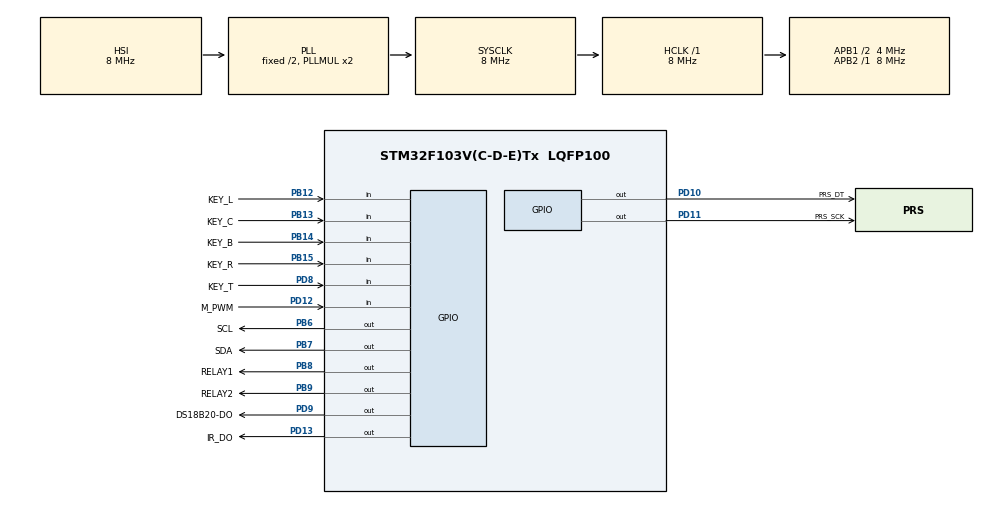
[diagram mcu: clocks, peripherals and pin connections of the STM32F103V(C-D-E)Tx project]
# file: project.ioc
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Mcu.Family=STM32F1
Mcu.Name=STM32F103V(C-D-E)Tx
Mcu.Package=LQFP100
NVIC.PriorityGroup=NVIC_PRIORITYGROUP_4
PA13.Mode=Serial_Wire
PA13.Signal=SYS_JTMS-SWDIO
PA14.Mode=Serial_Wire
PA14.Signal=SYS_JTCK-SWCLK
PB12.GPIO_Label=KEY_L
PB12.Signal=GPIO_Input
PB13.GPIO_Label=KEY_C
PB13.Signal=GPIO_Input
PB14.GPIO_Label=KEY_B
PB14.Signal=GPIO_Input
PB15.GPIO_Label=KEY_R
PB15.Signal=GPIO_Input
PB6.GPIO_Label=SCL
PB6.Signal=GPIO_Output
PB7.GPIO_Label=SDA
PB7.Signal=GPIO_Output
PB8.GPIO_Label=RELAY1
PB8.Signal=GPIO_Output
PB9.GPIO_Label=RELAY2
PB9.Signal=GPIO_Output
PD10.GPIO_Label=PRS_DT
PD10.Signal=GPIO_Output
PD11.GPIO_Label=PRS_SCK
PD11.Signal=GPIO_Output
PD12.GPIO_Label=M_PWM
PD12.Signal=GPIO_Input
PD13.GPIO_Label=IR_DO
PD13.Signal=GPIO_Output
PD8.GPIO_Label=KEY_T
PD8.Signal=GPIO_Input
PD9.GPIO_Label=DS18B20-DO
PD9.Signal=GPIO_Output
ProjectManager.HeapSize=0x200
ProjectManager.StackSize=0x400
ProjectManager.TargetToolchain=MDK-ARM V5.32
RCC.ADCPresc=RCC_ADCPCLK2_DIV6
RCC.AHBFreq_Value=8000000
RCC.APB1CLKDivider=RCC_HCLK_DIV2
RCC.APB1Freq_Value=4000000
RCC.APB1TimFreq_Value=8000000
RCC.APB2Freq_Value=8000000
RCC.APB2TimFreq_Value=8000000
RCC.HCLKFreq_Value=8000000
RCC.SYSCLKFreq_VALUE=8000000
RCC.SYSCLKSource=RCC_SYSCLKSOURCE_PLLCLK
RCC.USBFreq_Value=8000000
board=custom

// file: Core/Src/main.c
/* USER CODE BEGIN Header */
/**
  ******************************************************************************
  * @file           : main.c
  * @brief          : Main program body
  ******************************************************************************
  * @attention
  *
  * Copyright (c) 2026 STMicroelectronics.
  * All rights reserved.
  *
  * This software is licensed under terms that can be found in the LICENSE file
  * in the root directory of this software component.
  * If no LICENSE file comes with this software, it is provided AS-IS.
  *
  ******************************************************************************
  */
/* USER CODE END Header */
#include "main.h"
#include "gpio.h"

/* USER CODE BEGIN Includes */
#include "OLED.h"
/* USER CODE END Includes */

void SystemClock_Config(void);

int main(void)
{

  /* MCU Configuration--------------------------------------------------------*/

  /* Reset of all peripherals, Initializes the Flash interface and the Systick. */
  HAL_Init();

  /* Configure the system clock */
  SystemClock_Config();

  /* Initialize all configured peripherals */
  MX_GPIO_Init();
  /* USER CODE BEGIN 2 */
  OLED_Init();
  /* USER CODE END 2 */

  /* Infinite loop */
  /* USER CODE BEGIN WHILE */
  while (1)
  {

    OLED_DrawRectangle(0, 0, 128, 64, OLED_FILLED);
    OLED_Update();
    /* USER CODE END WHILE */

  }
}

void SystemClock_Config(void)
{
  RCC_OscInitTypeDef RCC_OscInitStruct = {0};
  RCC_ClkInitTypeDef RCC_ClkInitStruct = {0};

  /** Initializes the RCC Oscillators according to the specified parameters
  * in the RCC_OscInitTypeDef structure.
  */
  RCC_OscInitStruct.OscillatorType = RCC_OSCILLATORTYPE_HSI;
  RCC_OscInitStruct.HSIState = RCC_HSI_ON;
  RCC_OscInitStruct.HSICalibrationValue = RCC_HSICALIBRATION_DEFAULT;
  RCC_OscInitStruct.PLL.PLLState = RCC_PLL_ON;
  RCC_OscInitStruct.PLL.PLLSource = RCC_PLLSOURCE_HSI_DIV2;
  RCC_OscInitStruct.PLL.PLLMUL = RCC_PLL_MUL2;
  if (HAL_RCC_OscConfig(&RCC_OscInitStruct) != HAL_OK)
  {
    Error_Handler();
  }

  /** Initializes the CPU, AHB and APB buses clocks
  */
  RCC_ClkInitStruct.ClockType = RCC_CLOCKTYPE_HCLK|RCC_CLOCKTYPE_SYSCLK
                              |RCC_CLOCKTYPE_PCLK1|RCC_CLOCKTYPE_PCLK2;
  RCC_ClkInitStruct.SYSCLKSource = RCC_SYSCLKSOURCE_PLLCLK;
  RCC_ClkInitStruct.AHBCLKDivider = RCC_SYSCLK_DIV1;
  RCC_ClkInitStruct.APB1CLKDivider = RCC_HCLK_DIV2;
  RCC_ClkInitStruct.APB2CLKDivider = RCC_HCLK_DIV1;

  if (HAL_RCC_ClockConfig(&RCC_ClkInitStruct, FLASH_LATENCY_0) != HAL_OK)
  {
    Error_Handler();
  }
}

void Error_Handler(void)
{
  __disable_irq();
  while (1)
  {
  }
}
